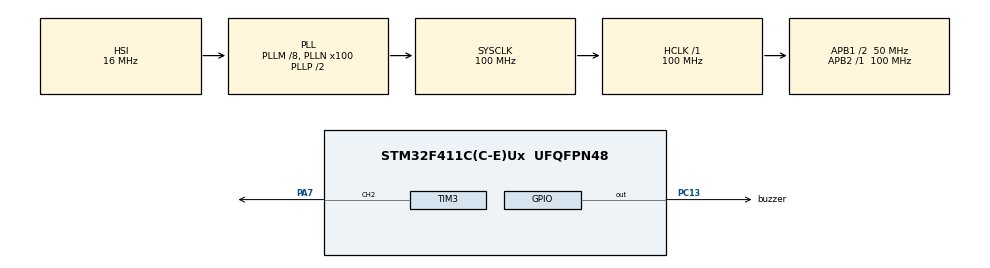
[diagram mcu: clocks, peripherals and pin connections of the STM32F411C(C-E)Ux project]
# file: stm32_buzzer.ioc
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Mcu.Family=STM32F4
Mcu.Name=STM32F411C(C-E)Ux
Mcu.Package=UFQFPN48
NVIC.PriorityGroup=NVIC_PRIORITYGROUP_4
PA13.Mode=Serial_Wire
PA13.Signal=SYS_JTMS-SWDIO
PA14.Mode=Serial_Wire
PA14.Signal=SYS_JTCK-SWCLK
PA7.Signal=S_TIM3_CH2
PC13-ANTI_TAMP.GPIO_Label=buzzer
PC13-ANTI_TAMP.Signal=GPIO_Output
PH0\ -\ OSC_IN.Mode=HSE-External-Oscillator
PH0\ -\ OSC_IN.Signal=RCC_OSC_IN
PH1\ -\ OSC_OUT.Mode=HSE-External-Oscillator
PH1\ -\ OSC_OUT.Signal=RCC_OSC_OUT
ProjectManager.HeapSize=0x200
ProjectManager.StackSize=0x400
ProjectManager.TargetToolchain=CMake
RCC.48MHZClocksFreq_Value=50000000
RCC.AHBFreq_Value=100000000
RCC.APB1CLKDivider=RCC_HCLK_DIV2
RCC.APB1Freq_Value=50000000
RCC.APB1TimFreq_Value=100000000
RCC.APB2Freq_Value=100000000
RCC.APB2TimFreq_Value=100000000
RCC.CortexFreq_Value=100000000
RCC.HCLKFreq_Value=100000000
RCC.HSE_VALUE=25000000
RCC.HSI_VALUE=16000000
RCC.LSE_VALUE=32768
RCC.PLLM=8
RCC.PLLN=100
RCC.SYSCLKFreq_VALUE=100000000
RCC.SYSCLKSource=RCC_SYSCLKSOURCE_PLLCLK
RCC.VCOOutputFreq_Value=200000000
SH.S_TIM3_CH2.0=TIM3_CH2,PWM Generation2 CH2
TIM3.Channel-PWM\ Generation2\ CH2=TIM_CHANNEL_2
TIM3.Period=2272
TIM3.Prescaler=99
TIM3.Pulse-PWM\ Generation2\ CH2=1136
VP_TIM3_VS_ClockSourceINT.Mode=Internal
board=custom

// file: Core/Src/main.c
/* USER CODE BEGIN Header */
/**
  ******************************************************************************
  * @file           : main.c
  * @brief          : Main program body
  ******************************************************************************
  * @attention
  *
  * Copyright (c) 2026 STMicroelectronics.
  * All rights reserved.
  *
  * This software is licensed under terms that can be found in the LICENSE file
  * in the root directory of this software component.
  * If no LICENSE file comes with this software, it is provided AS-IS.
  *
  ******************************************************************************
  */
/* USER CODE END Header */
#include "main.h"

/* USER CODE BEGIN Includes */
#include "buzzer.h"
#include "midi.h"
#include "songs.h"
/* USER CODE END Includes */

TIM_HandleTypeDef htim3;

void SystemClock_Config(void);
static void MX_GPIO_Init(void);
static void MX_TIM3_Init(void);
void HAL_TIM_MspPostInit(TIM_HandleTypeDef *htim);

/* USER CODE BEGIN 0 */
/* 发声/乐曲逻辑已封装到 buzzer.c / midi.c, 歌曲数据在 songs.c */

/* 播放配置: 改这里即可升音阶 / 变速 */
static const Midi_Config s_midi_cfg = {
  .transpose = 0,     /* 升/降半音: +12 = 升八度, +2 = 升全音, 负数降调 */
  .rate      = 100U,  /* 速率百分比: 100 = 原速, 200 = 快一倍, 50 = 慢一倍 */
};
/* USER CODE END 0 */

int main(void)
{

  /* MCU Configuration--------------------------------------------------------*/

  /* Reset of all peripherals, Initializes the Flash interface and the Systick. */
  HAL_Init();

  /* Configure the system clock */
  SystemClock_Config();

  /* Initialize all configured peripherals */
  MX_GPIO_Init();
  MX_TIM3_Init();
  /* USER CODE BEGIN 2 */
  /* 绑定发声模块到 TIM3_CH2 (计数时钟 1MHz), 按配置播放《兰花草》 */
  Buzzer_Init(&htim3, TIM_CHANNEL_2, 1000000U);
  Midi_PlayEx(&SONG_LanHuaCao, &s_midi_cfg);
  /* USER CODE END 2 */

  /* Infinite loop */
  while (1)
  {

    /* USER CODE BEGIN 3 */
    Midi_Task();
  }
  /* USER CODE END 3 */
}

void SystemClock_Config(void)
{
  RCC_OscInitTypeDef RCC_OscInitStruct = {0};
  RCC_ClkInitTypeDef RCC_ClkInitStruct = {0};

  /** Configure the main internal regulator output voltage
  */
  __HAL_RCC_PWR_CLK_ENABLE();
  __HAL_PWR_VOLTAGESCALING_CONFIG(PWR_REGULATOR_VOLTAGE_SCALE1);

  /** Initializes the RCC Oscillators according to the specified parameters
  * in the RCC_OscInitTypeDef structure.
  */
  RCC_OscInitStruct.OscillatorType = RCC_OSCILLATORTYPE_HSI;
  RCC_OscInitStruct.HSIState = RCC_HSI_ON;
  RCC_OscInitStruct.HSICalibrationValue = RCC_HSICALIBRATION_DEFAULT;
  RCC_OscInitStruct.PLL.PLLState = RCC_PLL_ON;
  RCC_OscInitStruct.PLL.PLLSource = RCC_PLLSOURCE_HSI;
  RCC_OscInitStruct.PLL.PLLM = 8;
  RCC_OscInitStruct.PLL.PLLN = 100;
  RCC_OscInitStruct.PLL.PLLP = RCC_PLLP_DIV2;
  RCC_OscInitStruct.PLL.PLLQ = 4;
  if (HAL_RCC_OscConfig(&RCC_OscInitStruct) != HAL_OK)
  {
    Error_Handler();
  }

  /** Initializes the CPU, AHB and APB buses clocks
  */
  RCC_ClkInitStruct.ClockType = RCC_CLOCKTYPE_HCLK|RCC_CLOCKTYPE_SYSCLK
                              |RCC_CLOCKTYPE_PCLK1|RCC_CLOCKTYPE_PCLK2;
  RCC_ClkInitStruct.SYSCLKSource = RCC_SYSCLKSOURCE_PLLCLK;
  RCC_ClkInitStruct.AHBCLKDivider = RCC_SYSCLK_DIV1;
  RCC_ClkInitStruct.APB1CLKDivider = RCC_HCLK_DIV2;
  RCC_ClkInitStruct.APB2CLKDivider = RCC_HCLK_DIV1;

  if (HAL_RCC_ClockConfig(&RCC_ClkInitStruct, FLASH_LATENCY_3) != HAL_OK)
  {
    Error_Handler();
  }
}

static void MX_TIM3_Init(void)
{

  TIM_ClockConfigTypeDef sClockSourceConfig = {0};
  TIM_MasterConfigTypeDef sMasterConfig = {0};
  TIM_OC_InitTypeDef sConfigOC = {0};

  htim3.Instance = TIM3;
  htim3.Init.Prescaler = 99;
  htim3.Init.CounterMode = TIM_COUNTERMODE_UP;
  htim3.Init.Period = 2272;
  htim3.Init.ClockDivision = TIM_CLOCKDIVISION_DIV1;
  htim3.Init.AutoReloadPreload = TIM_AUTORELOAD_PRELOAD_DISABLE;
  if (HAL_TIM_Base_Init(&htim3) != HAL_OK)
  {
    Error_Handler();
  }
  sClockSourceConfig.ClockSource = TIM_CLOCKSOURCE_INTERNAL;
  if (HAL_TIM_ConfigClockSource(&htim3, &sClockSourceConfig) != HAL_OK)
  {
    Error_Handler();
  }
  if (HAL_TIM_PWM_Init(&htim3) != HAL_OK)
  {
    Error_Handler();
  }
  sMasterConfig.MasterOutputTrigger = TIM_TRGO_RESET;
  sMasterConfig.MasterSlaveMode = TIM_MASTERSLAVEMODE_DISABLE;
  if (HAL_TIMEx_MasterConfigSynchronization(&htim3, &sMasterConfig) != HAL_OK)
  {
    Error_Handler();
  }
  sConfigOC.OCMode = TIM_OCMODE_PWM1;
  sConfigOC.Pulse = 1136;
  sConfigOC.OCPolarity = TIM_OCPOLARITY_HIGH;
  sConfigOC.OCFastMode = TIM_OCFAST_DISABLE;
  if (HAL_TIM_PWM_ConfigChannel(&htim3, &sConfigOC, TIM_CHANNEL_2) != HAL_OK)
  {
    Error_Handler();
  }
  HAL_TIM_MspPostInit(&htim3);

}

static void MX_GPIO_Init(void)
{
  GPIO_InitTypeDef GPIO_InitStruct = {0};

  /* GPIO Ports Clock Enable */
  __HAL_RCC_GPIOC_CLK_ENABLE();
  __HAL_RCC_GPIOH_CLK_ENABLE();
  __HAL_RCC_GPIOA_CLK_ENABLE();

  /*Configure GPIO pin Output Level */
  HAL_GPIO_WritePin(buzzer_GPIO_Port, buzzer_Pin, GPIO_PIN_RESET);

  /*Configure GPIO pin : buzzer_Pin */
  GPIO_InitStruct.Pin = buzzer_Pin;
  GPIO_InitStruct.Mode = GPIO_MODE_OUTPUT_PP;
  GPIO_InitStruct.Pull = GPIO_NOPULL;
  GPIO_InitStruct.Speed = GPIO_SPEED_FREQ_LOW;
  HAL_GPIO_Init(buzzer_GPIO_Port, &GPIO_InitStruct);

}

void Error_Handler(void)
{
  __disable_irq();
  while (1)
  {
  }
}
